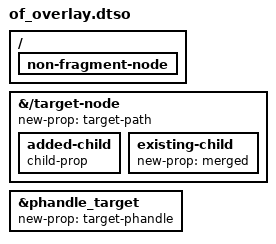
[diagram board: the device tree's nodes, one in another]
// SPDX-License-Identifier: GPL-2.0-only

/dts-v1/;
/plugin/;

/ {
	/* not a fragment, must not be applied */
	non-fragment-node {
	};

	fragment@0 {
		target-path = "/target-node";

		__overlay__ {
			new-prop = "target-path";

			added-child {
				child-prop;
			};

			existing-child {
				new-prop = "merged";
			};
		};
	};

	fragment@1 {
		target = <&phandle_target>;

		__overlay__ {
			new-prop = "target-phandle";
		};
	};
};
